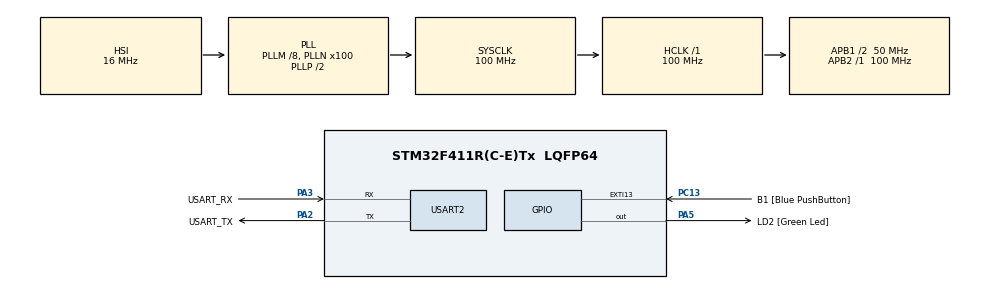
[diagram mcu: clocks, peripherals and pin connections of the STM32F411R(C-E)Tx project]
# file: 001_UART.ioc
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Mcu.Family=STM32F4
Mcu.Name=STM32F411R(C-E)Tx
Mcu.Package=LQFP64
NVIC.PriorityGroup=NVIC_PRIORITYGROUP_0
PA13.GPIO_Label=TMS
PA13.Signal=SYS_JTMS-SWDIO
PA14.GPIO_Label=TCK
PA14.Signal=SYS_JTCK-SWCLK
PA2.GPIO_Label=USART_TX
PA2.Mode=Asynchronous
PA2.Signal=USART2_TX
PA3.GPIO_Label=USART_RX
PA3.Mode=Asynchronous
PA3.Signal=USART2_RX
PA5.GPIO_Label=LD2 [Green Led]
PA5.Signal=GPIO_Output
PB3.GPIO_Label=SWO
PB3.Signal=SYS_JTDO-SWO
PC13-ANTI_TAMP.GPIO_Label=B1 [Blue PushButton]
PC13-ANTI_TAMP.GPIO_ModeDefaultEXTI=GPIO_MODE_IT_FALLING
PC13-ANTI_TAMP.Signal=GPXTI13
PC14-OSC32_IN.Mode=LSE-External-Oscillator
PC14-OSC32_IN.Signal=RCC_OSC32_IN
PC15-OSC32_OUT.Mode=LSE-External-Oscillator
PC15-OSC32_OUT.Signal=RCC_OSC32_OUT
PH0\ -\ OSC_IN.Mode=HSE-External-Clock-Source
PH0\ -\ OSC_IN.Signal=RCC_OSC_IN
PH1\ -\ OSC_OUT.Mode=HSE-External-Clock-Source
PH1\ -\ OSC_OUT.Signal=RCC_OSC_OUT
ProjectManager.HeapSize=0x200
ProjectManager.StackSize=0x400
ProjectManager.TargetToolchain=CMake
RCC.48MHZClocksFreq_Value=50000000
RCC.AHBFreq_Value=100000000
RCC.APB1CLKDivider=RCC_HCLK_DIV2
RCC.APB1Freq_Value=50000000
RCC.APB1TimFreq_Value=100000000
RCC.APB2Freq_Value=100000000
RCC.APB2TimFreq_Value=100000000
RCC.CortexFreq_Value=100000000
RCC.FLatency-AdvancedSettings=FLASH_LATENCY_3
RCC.HCLKFreq_Value=100000000
RCC.HSE_VALUE=8000000
RCC.HSI_VALUE=16000000
RCC.PLLM=8
RCC.PLLN=100
RCC.RCC_RTC_Clock_Source=RCC_RTCCLKSOURCE_LSE
RCC.SYSCLKFreq_VALUE=100000000
RCC.SYSCLKSource=RCC_SYSCLKSOURCE_PLLCLK
RCC.VCOOutputFreq_Value=200000000
USART2.VirtualMode=VM_ASYNC
VP_RTC_VS_RTC_Activate.Mode=RTC_Enabled
board=NUCLEO-F411RE

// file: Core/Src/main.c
/* USER CODE BEGIN Header */
/**
  ******************************************************************************
  * @file           : main.c
  * @brief          : Main program body
  ******************************************************************************
  * @attention
  *
  * Copyright (c) 2025 STMicroelectronics.
  * All rights reserved.
  *
  * This software is licensed under terms that can be found in the LICENSE file
  * in the root directory of this software component.
  * If no LICENSE file comes with this software, it is provided AS-IS.
  *
  ******************************************************************************
  */
/* USER CODE END Header */
#include "main.h"

/* USER CODE BEGIN Includes */
#include <string.h> //문자열 처리 함수들(strlen, strcpy, memset 등)을 사용하기 위해서 불러온다.
#include <stdio.h>  //sprintf() 등 입출력 관련 함수들을 사용하기 위한 헤더를 불러온다.
/* USER CODE END Includes */

RTC_HandleTypeDef hrtc;

UART_HandleTypeDef huart2;

/* USER CODE BEGIN PV */
int i = 0; // i를 점차 증가시키는 걸 확인하기 위해서 변수 선언
uint8_t uartBuffer[512]; //HAL_UART_Trasmit()함수에 보낼 문자열 데이터를 저장하는 버터 512로 선언하면 512바이트까지 가능하다.
/* USER CODE END PV */

void SystemClock_Config(void);
static void MX_GPIO_Init(void);
static void MX_RTC_Init(void);
static void MX_USART2_UART_Init(void);

int main(void)
{

  /* MCU Configuration--------------------------------------------------------*/

  /* Reset of all peripherals, Initializes the Flash interface and the Systick. */
  HAL_Init();

  /* Configure the system clock */
  SystemClock_Config();

  /* Initialize all configured peripherals */
  MX_GPIO_Init();
  MX_RTC_Init();
  MX_USART2_UART_Init();
  /* USER CODE BEGIN 2 */
  sprintf((char *)uartBuffer, "Hello World\n"); //sprintf()는 문자열을 버퍼에 포맷 형식대로 저장하는 함수, sprintf는 char형태로 넣어줘야해서 변환해서 넣고, 한글자씩 저장되어서 통신되는 느낌
  HAL_UART_Transmit(&huart2, uartBuffer, strlen((char *)uartBuffer), 100);
  // uart2 방식으로 통신하고, 위에서 sprintf를 통해서 저장된 버터값으로 통신, strlen은 전송할 데이터의 길이를 계산(여기서는 12바이트), 100ms 안에 송신이 안되면 오류로 간주한다.
  /* USER CODE END 2 */

  /* Infinite loop */
  /* USER CODE BEGIN WHILE */
  while (1)
  {
    sprintf((char *)uartBuffer, "received: %d\n", i); // 이건 문자열 "received: 0\n", "received: 1\n" 이런 식으로 만듦 -> i에 따라서
    HAL_UART_Transmit(&huart2, uartBuffer, strlen((char *)uartBuffer), 100); // 위에 설명이랑 똑같고
    i++; // 파이썬에서 i += 1 이런식으로 i를 증가하는 시킨다.
    HAL_Delay(1000);
    /* USER CODE END WHILE */

  }
}

void SystemClock_Config(void)
{
  RCC_OscInitTypeDef RCC_OscInitStruct = {0};
  RCC_ClkInitTypeDef RCC_ClkInitStruct = {0};

  /** Configure the main internal regulator output voltage
  */
  __HAL_RCC_PWR_CLK_ENABLE();
  __HAL_PWR_VOLTAGESCALING_CONFIG(PWR_REGULATOR_VOLTAGE_SCALE1);

  /** Initializes the RCC Oscillators according to the specified parameters
  * in the RCC_OscInitTypeDef structure.
  */
  RCC_OscInitStruct.OscillatorType = RCC_OSCILLATORTYPE_HSI|RCC_OSCILLATORTYPE_LSE;
  RCC_OscInitStruct.LSEState = RCC_LSE_ON;
  RCC_OscInitStruct.HSIState = RCC_HSI_ON;
  RCC_OscInitStruct.HSICalibrationValue = RCC_HSICALIBRATION_DEFAULT;
  RCC_OscInitStruct.PLL.PLLState = RCC_PLL_ON;
  RCC_OscInitStruct.PLL.PLLSource = RCC_PLLSOURCE_HSI;
  RCC_OscInitStruct.PLL.PLLM = 8;
  RCC_OscInitStruct.PLL.PLLN = 100;
  RCC_OscInitStruct.PLL.PLLP = RCC_PLLP_DIV2;
  RCC_OscInitStruct.PLL.PLLQ = 4;
  if (HAL_RCC_OscConfig(&RCC_OscInitStruct) != HAL_OK)
  {
    Error_Handler();
  }

  /** Initializes the CPU, AHB and APB buses clocks
  */
  RCC_ClkInitStruct.ClockType = RCC_CLOCKTYPE_HCLK|RCC_CLOCKTYPE_SYSCLK
                              |RCC_CLOCKTYPE_PCLK1|RCC_CLOCKTYPE_PCLK2;
  RCC_ClkInitStruct.SYSCLKSource = RCC_SYSCLKSOURCE_PLLCLK;
  RCC_ClkInitStruct.AHBCLKDivider = RCC_SYSCLK_DIV1;
  RCC_ClkInitStruct.APB1CLKDivider = RCC_HCLK_DIV2;
  RCC_ClkInitStruct.APB2CLKDivider = RCC_HCLK_DIV1;

  if (HAL_RCC_ClockConfig(&RCC_ClkInitStruct, FLASH_LATENCY_3) != HAL_OK)
  {
    Error_Handler();
  }
}

static void MX_RTC_Init(void)
{

  /** Initialize RTC Only
  */
  hrtc.Instance = RTC;
  hrtc.Init.HourFormat = RTC_HOURFORMAT_24;
  hrtc.Init.AsynchPrediv = 127;
  hrtc.Init.SynchPrediv = 255;
  hrtc.Init.OutPut = RTC_OUTPUT_DISABLE;
  hrtc.Init.OutPutPolarity = RTC_OUTPUT_POLARITY_HIGH;
  hrtc.Init.OutPutType = RTC_OUTPUT_TYPE_OPENDRAIN;
  if (HAL_RTC_Init(&hrtc) != HAL_OK)
  {
    Error_Handler();
  }

}

static void MX_USART2_UART_Init(void)
{

  huart2.Instance = USART2;
  huart2.Init.BaudRate = 115200;
  huart2.Init.WordLength = UART_WORDLENGTH_8B;
  huart2.Init.StopBits = UART_STOPBITS_1;
  huart2.Init.Parity = UART_PARITY_NONE;
  huart2.Init.Mode = UART_MODE_TX_RX;
  huart2.Init.HwFlowCtl = UART_HWCONTROL_NONE;
  huart2.Init.OverSampling = UART_OVERSAMPLING_16;
  if (HAL_UART_Init(&huart2) != HAL_OK)
  {
    Error_Handler();
  }

}

static void MX_GPIO_Init(void)
{
  GPIO_InitTypeDef GPIO_InitStruct = {0};

  /* GPIO Ports Clock Enable */
  __HAL_RCC_GPIOC_CLK_ENABLE();
  __HAL_RCC_GPIOH_CLK_ENABLE();
  __HAL_RCC_GPIOA_CLK_ENABLE();
  __HAL_RCC_GPIOB_CLK_ENABLE();

  /*Configure GPIO pin Output Level */
  HAL_GPIO_WritePin(LD2_GPIO_Port, LD2_Pin, GPIO_PIN_RESET);

  /*Configure GPIO pin : B1_Pin */
  GPIO_InitStruct.Pin = B1_Pin;
  GPIO_InitStruct.Mode = GPIO_MODE_IT_FALLING;
  GPIO_InitStruct.Pull = GPIO_NOPULL;
  HAL_GPIO_Init(B1_GPIO_Port, &GPIO_InitStruct);

  /*Configure GPIO pin : LD2_Pin */
  GPIO_InitStruct.Pin = LD2_Pin;
  GPIO_InitStruct.Mode = GPIO_MODE_OUTPUT_PP;
  GPIO_InitStruct.Pull = GPIO_NOPULL;
  GPIO_InitStruct.Speed = GPIO_SPEED_FREQ_LOW;
  HAL_GPIO_Init(LD2_GPIO_Port, &GPIO_InitStruct);

}

void Error_Handler(void)
{
  __disable_irq();
  while (1)
  {
  }
}
